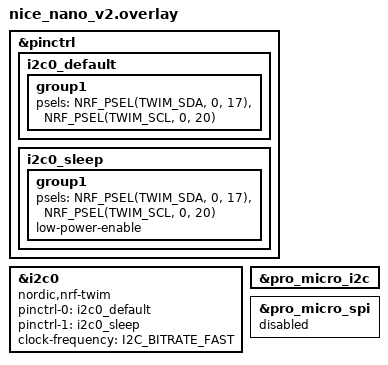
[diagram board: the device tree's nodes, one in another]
// https://github.com/zmkfirmware/zmk/blob/e93cd31a5866cd4f50385bece7a3fb770f2ca6f8/app/boards/arm/nice_nano/nice_nano-pinctrl.dtsi

&pinctrl {
    /* configuration for i2c0 device, default state */
    i2c0_default: i2c0_default {
        group1 {
            psels = <NRF_PSEL(TWIM_SDA, 0, 17)>,
                <NRF_PSEL(TWIM_SCL, 0, 20)>;
        };
    };

    i2c0_sleep: i2c0_sleep {
        group1 {
            psels = <NRF_PSEL(TWIM_SDA, 0, 17)>,
                <NRF_PSEL(TWIM_SCL, 0, 20)>;
            low-power-enable;
        };
    };
}

cirque_pinnacle_i2c: &i2c0 {
    compatible = "nordic,nrf-twim";

    status = "okay";
    pinctrl-0 = <&i2c0_default>;
    pinctrl-1 = <&i2c0_sleep>;
    pinctrl-names = "default", "sleep";
    clock-frequency = <I2C_BITRATE_FAST>;
};

&pro_micro_i2c {
    status = "okay";
};

&pro_micro_spi {
    status = "disabled";
};
